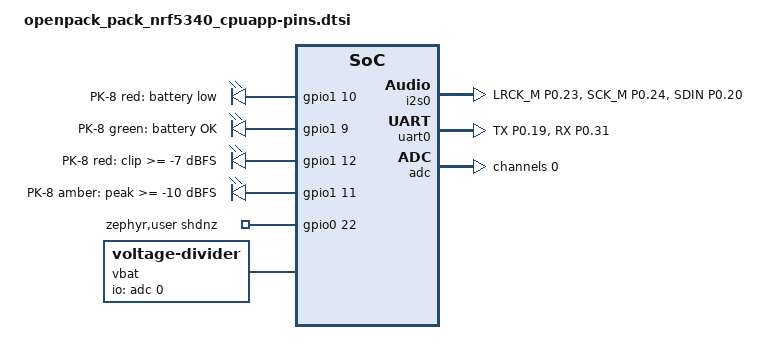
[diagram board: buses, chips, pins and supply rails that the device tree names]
/* GENERATED by fw/boards/openpack/gen_pins.py from hw/pack/out/pack.net (hw/pack/pack.py, ADR-0012). Do not edit:
 * change the schematic, rerun hw/pack/pack.py, then gen_pins.py.
 * openpack_pack/nrf5340/cpuapp. tests/test_fw_board_pins.py checks it against the netlist. */

&pinctrl {
	/* i2s0: I2S_LRCK_M=I2S_FSYNC@C4, I2S_SCK_M=I2S_BCLK@C3, I2S_SDIN=I2S_SDOUT@C5 */
	i2s0_default: i2s0_default {
		group1 {
			psels = <NRF_PSEL(I2S_LRCK_M, 0, 23)>,
				<NRF_PSEL(I2S_SCK_M, 0, 24)>,
				<NRF_PSEL(I2S_SDIN, 0, 20)>;
		};
	};
	i2s0_sleep: i2s0_sleep {
		group1 {
			psels = <NRF_PSEL(I2S_LRCK_M, 0, 23)>,
				<NRF_PSEL(I2S_SCK_M, 0, 24)>,
				<NRF_PSEL(I2S_SDIN, 0, 20)>;
			low-power-enable;
		};
	};
	/* uart0: UART_RX=UART_RX@C1, UART_TX=UART_TX@B1 */
	uart0_default: uart0_default {
		group1 {
			psels = <NRF_PSEL(UART_TX, 0, 19)>;
		};
		group2 {
			psels = <NRF_PSEL(UART_RX, 0, 31)>;
			bias-pull-up;
		};
	};
	uart0_sleep: uart0_sleep {
		group1 {
			psels = <NRF_PSEL(UART_TX, 0, 19)>;
			low-power-enable;
		};
		group2 {
			psels = <NRF_PSEL(UART_RX, 0, 31)>;
			low-power-enable;
			bias-pull-up;
		};
	};
};

&i2s0 {
	pinctrl-0 = <&i2s0_default>;
	pinctrl-1 = <&i2s0_sleep>;
	pinctrl-names = "default", "sleep";
};

&uart0 {
	pinctrl-0 = <&uart0_default>;
	pinctrl-1 = <&uart0_sleep>;
	pinctrl-names = "default", "sleep";
};

/ {
	leds {
		compatible = "gpio-leds";
		led_bat_low: led_bat_low {
			gpios = <&gpio1 10 GPIO_ACTIVE_HIGH>; /* LED_BAT_LOW@Z1 */
			label = "PK-8 red: battery low";
		};
		led_bat_ok: led_bat_ok {
			gpios = <&gpio1 9 GPIO_ACTIVE_HIGH>; /* LED_BAT_OK@Z0 */
			label = "PK-8 green: battery OK";
		};
		led_clip: led_clip {
			gpios = <&gpio1 12 GPIO_ACTIVE_HIGH>; /* LED_CLIP@Z3 */
			label = "PK-8 red: clip >= -7 dBFS";
		};
		led_peak: led_peak {
			gpios = <&gpio1 11 GPIO_ACTIVE_HIGH>; /* LED_PEAK@Z2 */
			label = "PK-8 amber: peak >= -10 dBFS";
		};
	};

	zephyr,user {
		shdnz-gpios = <&gpio0 22 GPIO_ACTIVE_HIGH>; /* ADC_SHDNZ@D5 */
	};

	vbat: vbat {
		compatible = "voltage-divider";
		io-channels = <&adc 0>;
		/* VBAT_SENSE@5 (P0.04/AIN0): R12 1M from BAT+, R13 1M to GND */
		output-ohms = <1000000>;
		full-ohms = <2000000>;
	};

	/* net-core pins, handed over at net-core boot (SOC_NRF_GPIO_FORWARDER_FOR_NRF5340) */
	gpio_fwd: nrf-gpio-forwarder {
		compatible = "nordic,nrf-gpio-forwarder";
		status = "okay";

		net {
			gpios = <&gpio0 21 0>,
				<&gpio0 27 0>,
				<&gpio0 26 0>,
				<&gpio1 4 0>,
				<&gpio1 5 0>;
			/* nRF21540 tx-en-gpios@C2, nRF21540 rx-en-gpios@D2, nRF21540 pdn-gpios@D1, nRF21540 mode-gpios@E0, nRF21540 ant-sel-gpios@E1 */
		};
	};
};

&adc {
	#address-cells = <1>;
	#size-cells = <0>;

	channel@0 {
		reg = <0>;
		zephyr,gain = "ADC_GAIN_1_6"; /* 3.6 V full scale vs. 2.1 V at 4.2 V cell */
		zephyr,reference = "ADC_REF_INTERNAL";
		zephyr,acquisition-time = <ADC_ACQ_TIME(ADC_ACQ_TIME_MICROSECONDS, 40)>; /* high-Z divider */
		zephyr,input-positive = <NRF_SAADC_AIN0>; /* VBAT_SENSE@5 P0.04/AIN0 */
		zephyr,resolution = <12>;
		zephyr,oversampling = <4>;
	};
};
